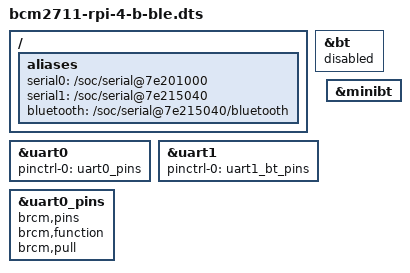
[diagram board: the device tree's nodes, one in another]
// SPDX-License-Identifier: GPL-2.0
#include "arm/broadcom/bcm2711-rpi-4-b.dts"

#include <dt-bindings/gpio/gpio.h>

// miniuart-bt
&uart0 {
	pinctrl-names = "default";
	pinctrl-0 = <&uart0_pins>;
	status = "okay";
};

&bt {
	status = "disabled";
};

&uart1 {
	pinctrl-names = "default";
	pinctrl-0 = <&uart1_pins>;
	status = "okay";
};

&uart0_pins {
	brcm,pins;
	brcm,function;
	brcm,pull;
};

&uart1 {
	pinctrl-0 = <&uart1_bt_pins>;
};

/ {
	aliases {
		serial0 = "/soc/serial@7e201000";
		serial1 = "/soc/serial@7e215040";
		bluetooth = "/soc/serial@7e215040/bluetooth";
	};
};

&minibt {
	status = "okay";
};
